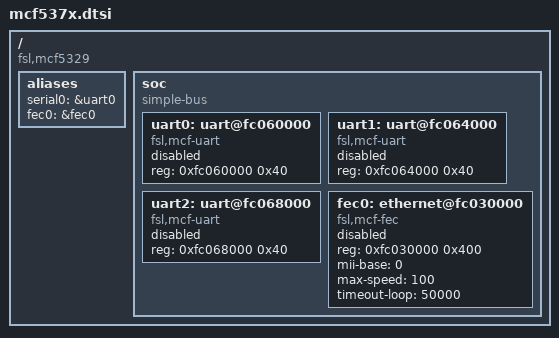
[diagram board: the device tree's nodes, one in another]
// SPDX-License-Identifier: GPL-2.0+
/*
 * Copyright (C) 2018 Angelo Dureghello <angelo@sysam.it>
 */

/ {
	compatible = "fsl,mcf5329";

	aliases {
		serial0 = &uart0;
		fec0 = &fec0;
	};

	soc {
		compatible = "simple-bus";
		#address-cells = <1>;
		#size-cells = <1>;

		uart0: uart@fc060000 {
			compatible = "fsl,mcf-uart";
			reg = <0xfc060000 0x40>;
			status = "disabled";
		};

		uart1: uart@fc064000 {
			compatible = "fsl,mcf-uart";
			reg = <0xfc064000 0x40>;
			status = "disabled";
		};

		uart2: uart@fc068000 {
			compatible = "fsl,mcf-uart";
			reg = <0xfc068000 0x40>;
			status = "disabled";
		};

		fec0: ethernet@fc030000 {
			compatible = "fsl,mcf-fec";
			reg = <0xfc030000 0x400>;
			mii-base = <0>;
			max-speed = <100>;
			timeout-loop = <50000>;
			status = "disabled";
		};
	};
};
